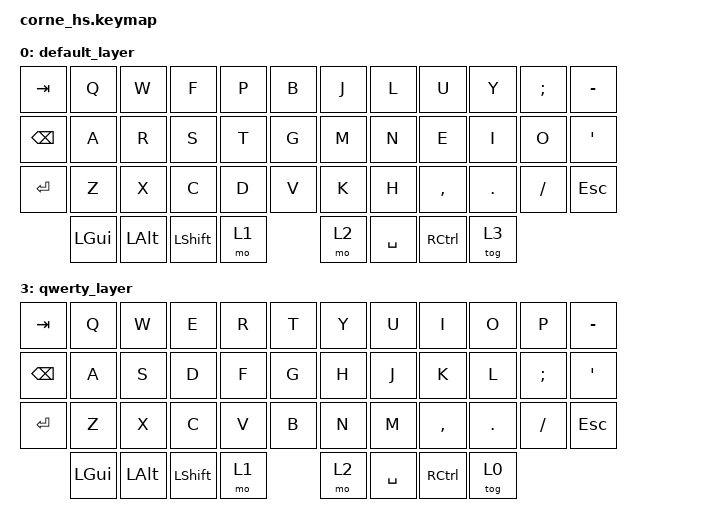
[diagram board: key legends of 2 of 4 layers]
/*
 * Copyright (c) 2020 The ZMK Contributors
 *
 * SPDX-License-Identifier: MIT
 */

#include <behaviors.dtsi>
#include <dt-bindings/zmk/keys.h>
#include <dt-bindings/zmk/bt.h>

/ {
        keymap {
                compatible = "zmk,keymap";

                default_layer {
// -----------------------------------------------------------------------------------------
// |  TAB |  Q  |  W  |  F  |  P  |  B  |   |  J  |  L  |  U  |  Y  |  ;  |  -   |
// | BKSP |  A  |  R  |  S  |  T  |  G  |   |  M  |  N  |  E  |  I  |  O  |  '   |
// | RET  |  Z  |  X  |  C  |  D  |  V  |   |  K  |  H  |  ,  |  .  |  /  | ESC  |
//              | GUI | ALT | SHFT| LWR |   | RSE | SPC | CTRL| SWP |
                        bindings = <
   &kp TAB   &kp Q &kp W &kp F &kp P &kp B   &kp J &kp L  &kp U     &kp Y   &kp SEMI &kp MINUS
   &kp BKSP  &kp A &kp R &kp S &kp T &kp G   &kp M &kp N  &kp E     &kp I   &kp O    &kp APOS
   &kp RET   &kp Z &kp X &kp C &kp D &kp V   &kp K &kp H  &kp COMMA &kp DOT &kp FSLH &kp ESC
          &kp LGUI &kp LALT &kp LSHFT &mo 1  &mo 2 &kp SPACE &kp RCTRL &tog 3 
                        >;
                };
                lower_layer {
// -----------------------------------------------------------------------------------------
// |  TAB |  1  |  2  |  3  |  4  |  5  |   |  6  |  7  |  8  |  9  |  0  | BKSP |
// | BTCLR| BT1 | BT2 | BT3 | BT4 | BT5 |   | LFT | DWN |  UP | RGT |     |      |
// | SHFT |     |     |     |     |     |   |     |     |     |     |     |      |
//                    | GUI |     | SPC |   | ENT |     | ALT |
                        bindings = <
   &kp TAB    &kp N1       &kp N2       &kp N3       &kp N4       &kp N5         &kp N6   &kp N7   &kp N8 &kp N9    &kp N0 &kp BSPC
   &bt BT_CLR &bt BT_SEL 0 &bt BT_SEL 1 &bt BT_SEL 2 &bt BT_SEL 3 &bt BT_SEL 4   &kp LEFT &kp DOWN &kp UP &kp RIGHT &trans &trans
   &kp LSHFT  &trans       &trans       &trans       &trans       &trans         &trans   &trans   &trans &trans    &trans &trans
                          	        &kp LGUI     &trans       &kp SPACE      &kp RET  &trans   &kp RALT
                        >;
                };

                raise_layer {
// -----------------------------------------------------------------------------------------
// |  TAB |  !  |  @  |  #  |  $  |  %  |   |  ^  |  &  |  *  |  (  |  )  | BKSP |
// | CTRL |     |     |     |     |     |   |  -  |  =  |  [  |  ]  |  \  |  `   |
// | SHFT |     |     |     |     |     |   |  _  |  +  |  {  |  }  | "|" |  ~   |
//                    | GUI |     | SPC |   | ENT |     | ALT |
                        bindings = <
   &kp  TAB  &kp EXCL &kp AT &kp HASH &kp DLLR &kp PRCNT   &kp CARET &kp AMPS  &kp KP_MULTIPLY &kp LPAR &kp RPAR &kp BSPC
   &kp LCTRL &trans   &trans &trans   &trans   &trans      &kp MINUS &kp EQUAL &kp LBKT        &kp RBKT &kp BSLH &kp GRAVE
   &kp LSHFT &trans   &trans &trans   &trans   &trans      &kp UNDER &kp PLUS  &kp LBRC        &kp RBRC &kp PIPE &kp TILDE
                    	     &kp LGUI &trans   &kp SPACE   &kp RET   &trans    &kp RALT
                        >;
                };

                qwerty_layer {
// -----------------------------------------------------------------------------------------
// |  TAB |  Q  |  W  |  E  |  R  |  T  |   |  Y  |  U   |  I  |  O  |  P  |  -   |
// | BKSP |  A  |  S  |  D  |  F  |  G  |   |  H  |  J   |  K  |  L  |  ;  |  '   |
// | RET  |  Z  |  X  |  C  |  V  |  B  |   |  N  |  M   |  ,  |  .  |  /  | ESC  |
//              | GUI | ALT | SHFT| LWR |   | RSE | SPC  | CTRL| SWP |
                        bindings = <
   &kp TAB  &kp Q &kp W &kp E &kp R &kp T   &kp Y &kp U  &kp I     &kp O   &kp P    &kp MINUS 
   &kp BSPC &kp A &kp S &kp D &kp F &kp G   &kp H &kp J  &kp K     &kp L   &kp SEMI &kp APOS
   &kp RET  &kp Z &kp X &kp C &kp V &kp B   &kp N &kp M  &kp COMMA &kp DOT &kp FSLH &kp ESC
          &kp LGUI &kp LALT &kp LSHFT &mo 1  &mo 2 &kp SPACE &kp RCTRL &tog 0 
                        >;
                };
        };
};
